# ADuCM320i register map
Vendor: Analog Devices Inc.; Series: ARMCM3; File version: 1.0
CPU: CM3 r2p1, little endian, no MPU, no FPU, 3 interrupt priority bits
Registers are 16-bit, read-write, no defined reset value unless marked. A register's access mark holds for its fields unless they carry their own. Offsets are from the block's base; [hi:lo] are bit positions; 'fields as' and 'values as' point back to an identical list.

## I2C0 — I2C0 Master/Slave
Base 0x40003000
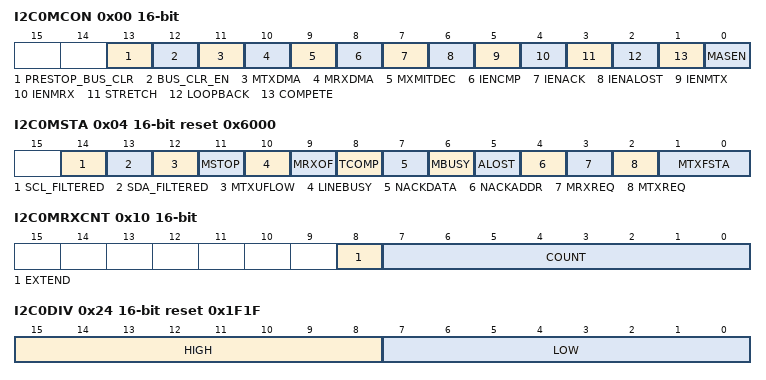
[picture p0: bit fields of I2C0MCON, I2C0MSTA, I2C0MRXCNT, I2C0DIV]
0x00 I2C0MCON — Master control register
  [13] PRESTOP_BUS_CLR range 0x00000000..0x00000001 — Prestop Bus-Clear
  [12] BUS_CLR_EN range 0x00000000..0x00000001 — Bus-Clear Enable
  [11] MTXDMA wo — Enable master Tx DMA request
    0=DIS (Disable DMA mode); 1=EN (Enable I2C master DMA Tx requests.)
  [10] MRXDMA wo — Enable master Rx DMA request
    0=DIS (Disable DMA mode); 1=EN (Enable I2C master DMA Rx requests.)
  [9] MXMITDEC range 0x00000000..0x00000001 — Decrement master TX FIFO status when a byte has been transmitted
  [8] IENCMP — Transaction completed (or stop detected) interrupt enable
    0=DIS (An interrupt is not generated when a STOP is detected.); 1=EN (An interrupt is generated when a STOP is detected.)
  [7] IENACK — ACK not received interrupt enable
    0=DIS (ACK not received interrupt disable); 1=EN (ACK not received interrupt enable)
  [6] IENALOST — Arbitration lost interrupt enable
    0=DIS (Arbitration lost interrupt disable); 1=EN (Arbitration lost interrupt enable)
  [5] IENMTX — Transmit request interrupt enable
    0=DIS (Transmit request interrupt disable); 1=EN (Transmit request interrupt enable)
  [4] IENMRX — Receive request interrupt enable
    0=DIS (Receive request interrupt disable); 1=EN (Receive request interrupt enable)
  [3] STRETCH — Stretch SCL enable
    0=DIS (Disable Clock stretching); 1=EN (Setting this bit tells the device if SCL is 0 hold it at 0;. Or if SCL is 1 then when it next goes to 0 hold it at 0.)
  [2] LOOPBACK — Internal loopback enable
    0=DIS (SCL and SDA out of the device are not muxed onto their corresponding inputs.); 1=EN (SCL and SDA out of the device are muxed onto their corresponding inputs.)
  [1] COMPETE range 0x00000000..0x00000001 — Start back-off disable
  [0] MASEN — Master enable
    0=DIS (Master is disabled); 1=EN (Master is enabled)
0x04 I2C0MSTA ro reset 0x6000 (reset mask 0x0) — Master status register
  [14] SCL_FILTERED range 0x00000000..0x00000001 — State of SCL Line
  [13] SDA_FILTERED range 0x00000000..0x00000001 — State of SDA Line
  [12] MTXUFLOW range 0x00000000..0x00000001 — Master Transmit Underflow
  [11] MSTOP range 0x00000000..0x00000001 — STOP driven by this I2C Master
  [10] LINEBUSY range 0x00000000..0x00000001 — Line is busy
  [9] MRXOF range 0x00000000..0x00000001 — Master Receive FIFO overflow
  [8] TCOMP range 0x00000000..0x00000001 — Transaction complete or stop detected
  [7] NACKDATA range 0x00000000..0x00000001 — ACK not received in response to data write
  [6] MBUSY range 0x00000000..0x00000001 — Master busy
  [5] ALOST range 0x00000000..0x00000001 — Arbitration lost
  [4] NACKADDR range 0x00000000..0x00000001 — ACK not received in response to an address
  [3] MRXREQ range 0x00000000..0x00000001 — Master Receive request
  [2] MTXREQ range 0x00000000..0x00000001 — Master Transmit request
  [1:0] MTXFSTA range 0x00000000..0x00000003 — Master Transmit FIFO status
0x08 I2C0MRX ro — Master receive data register
  [7:0] ICMRX range 0x00000000..0x000000FF — Master receive register
0x0C I2C0MTX — Master transmit data register
  [7:0] I2CMTX range 0x00000000..0x000000FF — Master transmit register
0x10 I2C0MRXCNT — Master receive data count register
  [8] EXTEND range 0x00000000..0x00000001 — Extended read
  [7:0] COUNT range 0x00000000..0x000000FF — Receive count
0x14 I2C0MCRXCNT ro — Master current receive data count register
  [7:0] COUNT range 0x00000000..0x000000FF — Current receive count
0x18 I2C0ADR0 — 1st master address byte register
  [7:0] ADR0 range 0x00000000..0x000000FF — Address byte 0
0x1C I2C0ADR1 — 2nd master address byte register
  [7:0] ADR1 range 0x00000000..0x000000FF — Address byte 1
0x24 I2C0DIV reset 0x1F1F (reset mask 0x0) — Serial clock period divisor register
  [15:8] HIGH range 0x00000000..0x000000FF — Serial clock high time
  [7:0] LOW range 0x00000000..0x000000FF — Serial clock low time
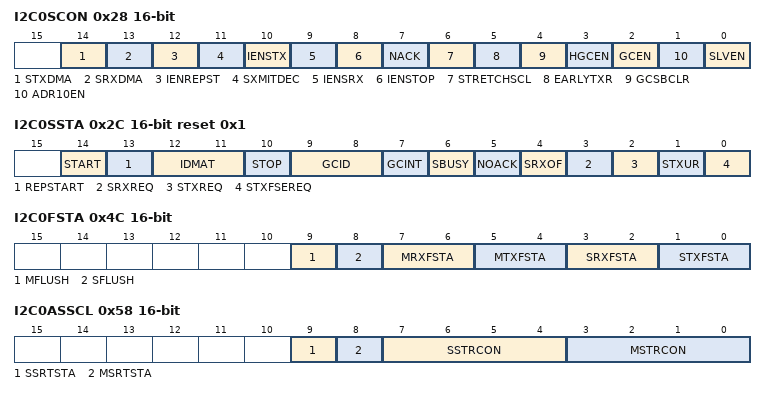
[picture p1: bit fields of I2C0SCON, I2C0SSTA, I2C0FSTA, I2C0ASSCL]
0x28 I2C0SCON — Slave control register
  [14] STXDMA range 0x00000000..0x00000001 — Enable slave Tx DMA request
  [13] SRXDMA range 0x00000000..0x00000001 — Enable slave Rx DMA request
  [12] IENREPST range 0x00000000..0x00000001 — Repeated start interrupt enable
  [11] SXMITDEC range 0x00000000..0x00000001 — Decrement Slave Tx FIFO status when a byte has been transmitted
  [10] IENSTX range 0x00000000..0x00000001 — Slave Transmit request interrupt enable
  [9] IENSRX range 0x00000000..0x00000001 — Slave Receive request interrupt enable
  [8] IENSTOP range 0x00000000..0x00000001 — Stop condition detected interrupt enable
  [7] NACK range 0x00000000..0x00000001 — NACK next communication
  [6] STRETCHSCL range 0x00000000..0x00000001 — Stretch SCL enable
  [5] EARLYTXR range 0x00000000..0x00000001 — Early transmit request mode
  [4] GCSBCLR wo range 0x00000000..0x00000001 — General call status bit clear
  [3] HGCEN range 0x00000000..0x00000001 — Hardware general call enable
  [2] GCEN range 0x00000000..0x00000001 — General call enable
  [1] ADR10EN range 0x00000000..0x00000001 — Enabled 10-bit addressing
  [0] SLVEN range 0x00000000..0x00000001 — Slave enable
0x2C I2C0SSTA ro reset 0x1 (reset mask 0x0) — Slave I2C Status/Error/IRQ register
  [14] START range 0x00000000..0x00000001 — Start and matching address
  [13] REPSTART range 0x00000000..0x00000001 — Repeated start and matching address
  [12:11] IDMAT range 0x00000000..0x00000003 — Device ID matched
  [10] STOP range 0x00000000..0x00000001 — Stop after start and matching address
  [9:8] GCID range 0x00000000..0x00000003 — General ID
  [7] GCINT range 0x00000000..0x00000001 — General call interrupt
  [6] SBUSY range 0x00000000..0x00000001 — Slave busy
  [5] NOACK range 0x00000000..0x00000001 — Ack not generated by the slave
  [4] SRXOF range 0x00000000..0x00000001 — Slave Receive FIFO overflow
  [3] SRXREQ range 0x00000000..0x00000001 — Slave Receive request
  [2] STXREQ range 0x00000000..0x00000001 — Slave Transmit request
  [1] STXUR range 0x00000000..0x00000001 — Slave Transmit FIFO underflow
  [0] STXFSEREQ range 0x00000000..0x00000001 — Slave Tx FIFO Status or early request
0x30 I2C0SRX ro — Slave receive register
  [7:0] I2CSRX range 0x00000000..0x000000FF
0x34 I2C0STX — Slave transmit register
  [7:0] I2CSTX range 0x00000000..0x000000FF
0x38 I2C0ALT — Hardware general call ID register
  [7:0] ALT range 0x00000000..0x000000FF — Slave Alt
0x3C I2C0ID0 — 1st slave address device ID register
  [7:0] ID0 range 0x00000000..0x000000FF — Slave device ID 0
0x40 I2C0ID1 — 2nd slave address device ID register
  [7:0] ID1 range 0x00000000..0x000000FF — Slave device ID 1
0x44 I2C0ID2 — 3rd slave address device ID register
  [7:0] ID2 range 0x00000000..0x000000FF — Slave device ID 2
0x48 I2C0ID3 — 4th slave address device ID register
  [7:0] ID3 range 0x00000000..0x000000FF — Slave device ID 3
0x4C I2C0FSTA — Master and slave FIFO status register
  [9] MFLUSH wo — Flush the master transmit FIFO
    0=DIS (Clearing to 0 has no effect.); 1=EN (Set to 1 to flush the master transmit FIFO. The master transmit FIFO will have to flushed if arbitration is lost or a slave responds with a NACK.)
  [8] SFLUSH wo — Flush the slave transmit FIFO
    0=DIS (Clearing to 0 has no effect.); 1=EN (Set to 1 to flush the slave transmit FIFO.)
  [7:6] MRXFSTA ro — Master receive FIFO status
    0=EMPTY (FIFO empty); 1=ONEBYTE (1 bytes in the FIFO); 2=TWOBYTES (2 bytes in the FIFO)
  [5:4] MTXFSTA ro — Master transmit FIFO status
    values as MRXFSTA
  [3:2] SRXFSTA ro — Slave receive FIFO status
    values as MRXFSTA
  [1:0] STXFSTA ro — Slave transmit FIFO status
    values as MRXFSTA
0x50 I2C0SHCON wo — Shared control register
  [0] RESET range 0x00000000..0x00000001 — Reset START STOP detect circuit
0x58 I2C0ASSCL — Automatic Stretch control register
  [9] SSRTSTA ro range 0x00000000..0x00000001 — stretch timeout for slave
  [8] MSRTSTA ro range 0x00000000..0x00000001 — stretch timeout for master
  [7:4] SSTRCON range 0x00000000..0x0000000F — automatic stretch mode for slave
  [3:0] MSTRCON range 0x00000000..0x0000000F — automatic stretch mode for master

## I2C1 — I2C1 Master/Slave
Base 0x40003400
Registers as I2C0 (with I2C0 read as I2C1); these are added or differ:
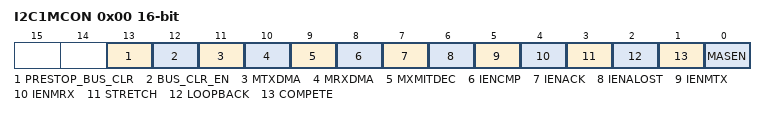
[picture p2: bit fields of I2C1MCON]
0x00 I2C1MCON — Master control register
  [13] PRESTOP_BUS_CLR range 0x00000000..0x00000001 — Prestop Bus-Clear
  [12] BUS_CLR_EN range 0x00000000..0x00000001 — Bus-Clear Enable
  [11] MTXDMA wo — Enable master Tx DMA request
    0=DIS (Disable DMA mode); 1=EN (Enable I2C master DMA Tx requests.)
  [10] MRXDMA wo — Enable master Rx DMA request
    0=DIS (Disable DMA mode); 1=EN (Enable I2C master DMA Rx requests.)
  [9] MXMITDEC range 0x00000000..0x00000001 — Decrement master TX FIFO status when a byte has been transmitted
  [8] IENCMP — Transaction completed (or stop detected) interrupt enable
    0=DIS (An interrupt is not generated when a STOP is detected.); 1=EN (An interrupt is generated when a STOP is detected.)
  [7] IENACK — ACK not received interrupt enable
    0=DIS (ACK not received interrupt disable); 1=EN (ACK not received interrupt enable)
  [6] IENALOST — Arbitration lost interrupt enable
    0=DIS (Arbitration lost interrupt disable); 1=EN (Arbitration lost interrupt enable)
  [5] IENMTX — Transmit request interrupt enable.
    0=DIS (Transmit request interrupt disable); 1=EN (Transmit request interrupt enable)
  [4] IENMRX — Receive request interrupt enable
    0=DIS (Receive request interrupt disable); 1=EN (Receive request interrupt enable)
  [3] STRETCH — Stretch SCL enable
    0=DIS (Disable Clock stretching); 1=EN (Setting this bit tells the device if SCL is 0 hold it at 0;. Or if SCL is 1 then when it next goes to 0 hold it at 0.)
  [2] LOOPBACK — Internal loopback enable
    0=DIS (SCL and SDA out of the device are not muxed onto their corresponding inputs.); 1=EN (SCL and SDA out of the device are muxed onto their corresponding inputs.)
  [1] COMPETE range 0x00000000..0x00000001 — Start back-off disable
  [0] MASEN — Master enable
    0=DIS (Master is disabled); 1=EN (Master is enabled)
